AUTOSAR XML (schema 4-2-2)
standard types defined: sint16, uint16, uint8, sint16_DataConstr, uint16_DataConstr, uint8_DataConstr, boolean
package /IoHwAb/Interface
  client server interface IoHwAb_HbrModCtrl
    operation Hbr_SetMod: possible-error=IoHwAb_HbrModCtrl/E_NOT_OK
      arg id_u16: type=ImplementationDataTypes/uint16, direction=IN, server-argument-impl-policy=USE-ARGUMENT-TYPE
      arg mod_u8: type=ImplementationDataTypes/uint8, direction=IN, server-argument-impl-policy=USE-ARGUMENT-TYPE
    error E_NOT_OK: error-code=1
  client server interface IoHwAb_IoSigAdc
    operation Adc_Get: possible-error=IoHwAb_IoSigAdc/E_NOT_OK
      arg id_u16: type=ImplementationDataTypes/uint16, direction=IN, server-argument-impl-policy=USE-ARGUMENT-TYPE
      arg val_s16: type=sint16, direction=OUT, server-argument-impl-policy=USE-ARGUMENT-TYPE
    operation AdcFac_Get: possible-error=IoHwAb_IoSigAdc/E_NOT_OK
      arg id_u16: type=ImplementationDataTypes/uint16, direction=IN, server-argument-impl-policy=USE-ARGUMENT-TYPE
      arg val_s16: type=sint16, direction=OUT, server-argument-impl-policy=USE-ARGUMENT-TYPE
    operation AdcVRMBatt_Get: possible-error=IoHwAb_IoSigAdc/E_NOT_OK
      arg id_u16: type=ImplementationDataTypes/uint16, direction=IN, server-argument-impl-policy=USE-ARGUMENT-TYPE
      arg val_u8: type=ImplementationDataTypes/uint8, direction=OUT, server-argument-impl-policy=USE-ARGUMENT-TYPE
    error E_NOT_OK: error-code=1
  client server interface IoHwAb_IoSigDio
    operation Di_Get: possible-error=IoHwAb_IoSigDio/E_NOT_OK
      arg id_u16: type=ImplementationDataTypes/uint16, direction=IN, server-argument-impl-policy=USE-ARGUMENT-TYPE
      arg val_u8: type=ImplementationDataTypes/uint8, direction=OUT, server-argument-impl-policy=USE-ARGUMENT-TYPE
    operation Do_Set: possible-error=IoHwAb_IoSigDio/E_NOT_OK
      arg id_u16: type=ImplementationDataTypes/uint16, direction=IN, server-argument-impl-policy=USE-ARGUMENT-TYPE
      arg val_u8: type=ImplementationDataTypes/uint8, direction=IN, server-argument-impl-policy=USE-ARGUMENT-TYPE
    error E_NOT_OK: error-code=1
package /UAES/ASW/ApplicationDataTypes
  app type Fac_q0p001_u16: category=VALUE, sw-calibration-access=READ-WRITE, compu {phys=raw*0.001 for raw -INF..INF}, range phys 0..65.535
package /UAES/ASW/CompuMethods
  compu method CM_boolean: 0=FALSE, 1=TRUE
package /UAES/ASW/DataConstrs
  range DC_boolean: raw 0..1
  range DC_uint16: phys 0..6553.5, raw 0..65535
  range DC_uint8: raw 0..255
package /UAES/ASW/DataTypeMappingSets
  data type mapping set DTMS_WND_DD: data-type-map{application-data-type=Fac_q0p001_u16, implementation-data-type=ImplementationDataTypes/uint16}
package /UAES/ASW/PortInterfaces
  11 x sender receiver interface:
    BattU_VrmFac1: invalidation-policy{data-element=BattU_VrmFac1/Val, handle-invalid=DONT-INVALIDATE}
      data Val: sw-calibration-access=READ-ONLY, type=Fac_q0p001_u16
    BattU_VrmFac2: invalidation-policy{data-element=BattU_VrmFac2/Val, handle-invalid=DONT-INVALIDATE}
      data Val: sw-calibration-access=READ-ONLY, type=Fac_q0p001_u16
    BattU_VrmFac3: invalidation-policy{data-element=BattU_VrmFac3/Val, handle-invalid=DONT-INVALIDATE}
      data Val: sw-calibration-access=READ-ONLY, type=Fac_q0p001_u16
    gASI_bRLDoorHSUSw: invalidation-policy{data-element=gASI_bRLDoorHSUSw/Val, handle-invalid=DONT-INVALIDATE}
      data Val: sw-calibration-access=READ-ONLY, type=boolean
    gASI_bRRDoorHSUSw: invalidation-policy{data-element=gASI_bRRDoorHSUSw/Val, handle-invalid=DONT-INVALIDATE}
      data Val: sw-calibration-access=READ-ONLY, type=boolean
    gASI_u8RLBossWindowSw: invalidation-policy{data-element=gASI_u8RLBossWindowSw/Val, handle-invalid=DONT-INVALIDATE}
      data Val: sw-calibration-access=READ-ONLY, type=ImplementationDataTypes/uint8
    gASI_u8RLLocalWindowSw: invalidation-policy{data-element=gASI_u8RLLocalWindowSw/Val, handle-invalid=DONT-INVALIDATE}
      data Val: sw-calibration-access=READ-ONLY, type=ImplementationDataTypes/uint8
    gASI_u8RRBossWindowSw: invalidation-policy{data-element=gASI_u8RRBossWindowSw/Val, handle-invalid=DONT-INVALIDATE}
      data Val: sw-calibration-access=READ-ONLY, type=ImplementationDataTypes/uint8
    gASI_u8RRLocalWindowSw: invalidation-policy{data-element=gASI_u8RRLocalWindowSw/Val, handle-invalid=DONT-INVALIDATE}
      data Val: sw-calibration-access=READ-ONLY, type=ImplementationDataTypes/uint8
    gWND_u8RLWinOutput: invalidation-policy{data-element=gWND_u8RLWinOutput/Val, handle-invalid=DONT-INVALIDATE}
      data Val: sw-calibration-access=READ-ONLY, type=ImplementationDataTypes/uint8
    gWND_u8RRWinOutput: invalidation-policy{data-element=gWND_u8RRWinOutput/Val, handle-invalid=DONT-INVALIDATE}
      data Val: sw-calibration-access=READ-ONLY, type=ImplementationDataTypes/uint8
package /UAES/ASW/SwComponentTypes
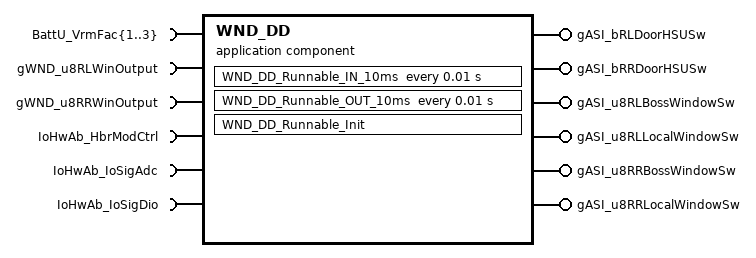
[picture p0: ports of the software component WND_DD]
  application sw component type WND_DD
    6 x provide port:
      gASI_bRLDoorHSUSw: nonqueued-sender-com-spec=data-element=gASI_bRLDoorHSUSw/Val, provided-interface=gASI_bRLDoorHSUSw
      gASI_bRRDoorHSUSw: nonqueued-sender-com-spec=data-element=gASI_bRRDoorHSUSw/Val, provided-interface=gASI_bRRDoorHSUSw
      gASI_u8RLBossWindowSw: nonqueued-sender-com-spec{data-element=gASI_u8RLBossWindowSw/Val, init-value=0}, provided-interface=gASI_u8RLBossWindowSw
      gASI_u8RLLocalWindowSw: nonqueued-sender-com-spec{data-element=gASI_u8RLLocalWindowSw/Val, init-value=0}, provided-interface=gASI_u8RLLocalWindowSw
      gASI_u8RRBossWindowSw: nonqueued-sender-com-spec{data-element=gASI_u8RRBossWindowSw/Val, init-value=0}, provided-interface=gASI_u8RRBossWindowSw
      gASI_u8RRLocalWindowSw: nonqueued-sender-com-spec{data-element=gASI_u8RRLocalWindowSw/Val, init-value=0}, provided-interface=gASI_u8RRLocalWindowSw
    8 x require port:
      BattU_VrmFac{1..3}: nonqueued-receiver-com-spec{data-element=BattU_VrmFac{1..3}/Val, filter=data-filter-type=ALWAYS, init-value=0}, required-interface=BattU_VrmFac{1..3}
      gWND_u8RLWinOutput: nonqueued-receiver-com-spec{data-element=gWND_u8RLWinOutput/Val, filter=data-filter-type=ALWAYS, init-value=0}, required-interface=gWND_u8RLWinOutput
      gWND_u8RRWinOutput: nonqueued-receiver-com-spec{data-element=gWND_u8RRWinOutput/Val, filter=data-filter-type=ALWAYS, init-value=0}, required-interface=gWND_u8RRWinOutput
      IoHwAb_HbrModCtrl: client-com-spec=Hbr_SetMod, required-interface=IoHwAb_HbrModCtrl
      IoHwAb_IoSigAdc: required-com-specs=[Adc_Get, AdcFac_Get, AdcVRMBatt_Get], required-interface=IoHwAb_IoSigAdc
      IoHwAb_IoSigDio: required-com-specs=[Di_Get, Do_Set], required-interface=IoHwAb_IoSigDio
    behavior WND_DD_InternalBehavior: data-type-mapping=DTMS_WND_DD
      timing event TMT_WND_DD_Runnable_IN_10ms: start-on-event=WND_DD_Runnable_IN_10ms, period=0.01
      init event WND_DD_InitEvent: start-on-event=WND_DD_Runnable_Init
      timing event TMT_WND_DD_Runnable_OUT_10ms: start-on-event=WND_DD_Runnable_OUT_10ms, period=0.01
      runnable WND_DD_Runnable_IN_10ms
        data-receive-point-by-arguments:
          access IN_BattU_VrmFac{1..3}_Val: accessed-variable=BattU_VrmFac{1..3}.Val
        data-send-points:
          6 x access:
            OUT_gASI_bRLDoorHSUSw_Val: accessed-variable=gASI_bRLDoorHSUSw.Val
            OUT_gASI_bRRDoorHSUSw_Val: accessed-variable=gASI_bRRDoorHSUSw.Val
            OUT_gASI_u8RLBossWindowSw_val: accessed-variable=gASI_u8RLBossWindowSw.Val
            OUT_gASI_u8RLLocalWindowSw_val: accessed-variable=gASI_u8RLLocalWindowSw.Val
            OUT_gASI_u8RRBossWindowSw_val: accessed-variable=gASI_u8RRBossWindowSw.Val
            OUT_gASI_u8RRLocalWindowSw_val: accessed-variable=gASI_u8RRLocalWindowSw.Val
        4 x sync call, all with timeout=0:
          SC_IoHwAb_IoSigAdc_Adc_Get: operation=IoHwAb_IoSigAdc.Adc_Get
          SC_IoHwAb_IoSigAdc_AdcFac_Get: operation=IoHwAb_IoSigAdc.AdcFac_Get
          SC_IoHwAb_IoSigAdc_AdcVRMBatt_Get: operation=IoHwAb_IoSigAdc.AdcVRMBatt_Get
          SC_IoHwAb_IoSigDio_Di_Get: operation=IoHwAb_IoSigDio.Di_Get
      runnable WND_DD_Runnable_Init
      runnable WND_DD_Runnable_OUT_10ms
        data-receive-point-by-arguments:
          access IN_gWND_u8RLWinOutput_val: accessed-variable=gWND_u8RLWinOutput.Val
          access IN_gWND_u8RRWinOutput_val: accessed-variable=gWND_u8RRWinOutput.Val
        sync call SC_IoHwAb_HbrModCtrl_Hbr_SetMod: operation=IoHwAb_HbrModCtrl.Hbr_SetMod, timeout=0
        sync call SC_IoHwAb_IoSigDio_Do_Set: operation=IoHwAb_IoSigDio.Do_Set, timeout=0
  swc implementation WND_DD_Implementation: behavior=WND_DD_InternalBehavior
    code-descriptors:
      code Default: artifact-descriptors=autosar-engineering-object={short-label=Default, category=SWSRC}
package /UAES/ASW/Units
  unit NoUnit: factor-si-to-unit=1, offset-si-to-unit=0
